# f28002x_cpu_sys_regs register map
Vendor: Texas Instruments
Peripheral module from a debugger description file (folder C2000).
Address unit: 16 bits
Registers are 32-bit, read-write, no defined reset value unless marked. A register's access mark holds for its fields unless they carry their own. Offsets are as the file gives them; lines under a group give offsets from that group; [hi:lo] are bit positions; {n}, {i} and the like mark numbered series; 'fields as' and 'values as' point back to an identical list; <NAME> marks a mode.

## CPU_SYS_REGS — CPU SYS Registers
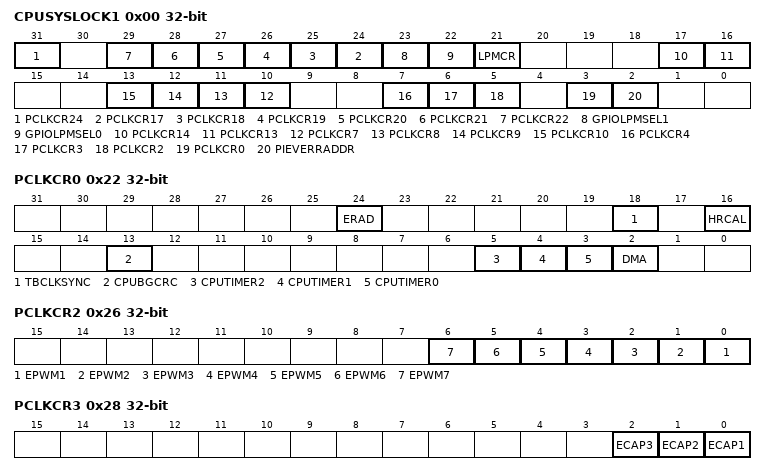
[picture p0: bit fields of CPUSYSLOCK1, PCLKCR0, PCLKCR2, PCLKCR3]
0x00 CPUSYSLOCK1 — Lock bit for CPUSYS registers
  [31] PCLKCR24 — Lock bit for PCLKCR24 Register
  [n+7] PCLKCR{n} (n=17..22) — Lock bit for PCLKCR{n} Register
  [23] GPIOLPMSEL1 — Lock bit for GPIOLPMSEL1 Register
  [22] GPIOLPMSEL0 — Lock bit for GPIOLPMSEL0 Register
  [21] LPMCR — Lock bit for LPMCR Register
  [17] PCLKCR14 — Lock bit for PCLKCR14 Register
  [16] PCLKCR13 — Lock bit for PCLKCR13 Register
  [n+3] PCLKCR{n} (n=7..10) — Lock bit for PCLKCR{n} Register
  [7] PCLKCR4 — Lock bit for PCLKCR4 Register
  [6] PCLKCR3 — Lock bit for PCLKCR3 Register
  [5] PCLKCR2 — Lock bit for PCLKCR2 Register
  [3] PCLKCR0 — Lock bit for PCLKCR0 Register
  [2] PIEVERRADDR — Lock bit for PIEVERRADDR Register
0x02 CPUSYSLOCK2 — Lock bit for CPUSYS registers
  [1] PCLKCR25 — Lock bit for PCLKCR25 Register
0x0A PIEVERRADDR — PIE Vector Fetch Error Address register
  [21:0] ADDR — PIE Vector Fetch Error Handler Routine Address
0x22 PCLKCR0 — Peripheral Clock Gating Registers
  [24] ERAD — ERAD module clock enable
  [18] TBCLKSYNC — EPWM Time Base Clock sync
  [16] HRCAL — HRCAL Clock Enable Bit
  [13] CPUBGCRC — CPUBGCRC Clock Enable Bit
  [5] CPUTIMER2 — CPUTIMER2 Clock Enable bit
  [4] CPUTIMER1 — CPUTIMER1 Clock Enable bit
  [3] CPUTIMER0 — CPUTIMER0 Clock Enable bit
  [2] DMA — DMA Clock Enable bit
0x26 PCLKCR2 — Peripheral Clock Gating Register - ETPWM
  [n-1] EPWM{n} (n=1..7) — EPWM{n} Clock Enable bit
0x28 PCLKCR3 — Peripheral Clock Gating Register - ECAP
  [2] ECAP3 — ECAP3 Clock Enable bit
  [1] ECAP2 — ECAP2 Clock Enable bit
  [0] ECAP1 — ECAP1 Clock Enable bit
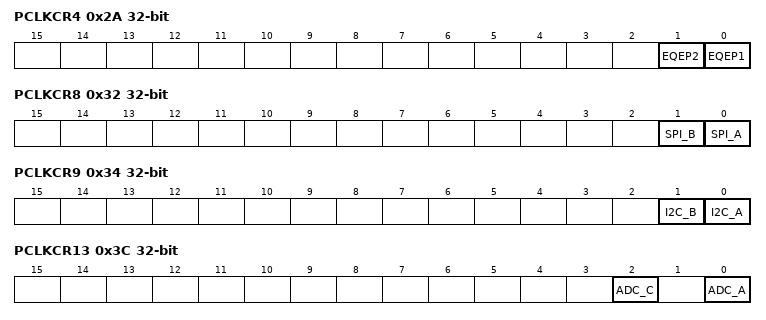
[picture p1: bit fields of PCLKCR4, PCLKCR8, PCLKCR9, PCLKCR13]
0x2A PCLKCR4 — Peripheral Clock Gating Register - EQEP
  [1] EQEP2 — EQEP2 Clock Enable bit
  [0] EQEP1 — EQEP1 Clock Enable bit
0x30 PCLKCR7 — Peripheral Clock Gating Register - SCI
  [0] SCI_A — SCI_A Clock Enable bit
0x32 PCLKCR8 — Peripheral Clock Gating Register - SPI
  [1] SPI_B — SPI_B Clock Enable bit
  [0] SPI_A — SPI_A Clock Enable bit
0x34 PCLKCR9 — Peripheral Clock Gating Register - I2C
  [1] I2C_B — I2C_B Clock Enable bit
  [0] I2C_A — I2C_A Clock Enable bit
0x36 PCLKCR10 — Peripheral Clock Gating Register - CAN
  [0] CAN_A — CAN_A Clock Enable bit
0x3C PCLKCR13 — Peripheral Clock Gating Register - ADC
  [2] ADC_C — ADC_C Clock Enable bit
  [0] ADC_A — ADC_A Clock Enable bit
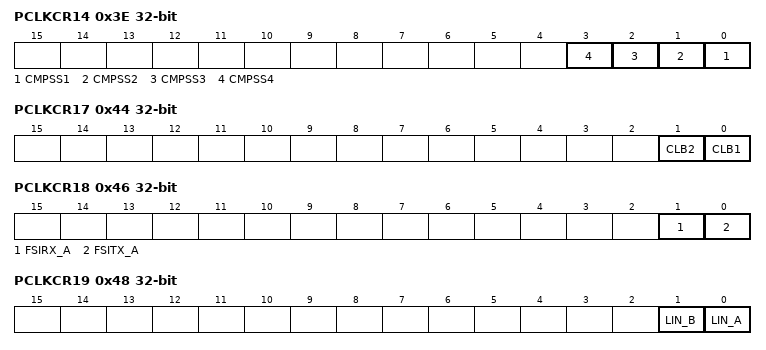
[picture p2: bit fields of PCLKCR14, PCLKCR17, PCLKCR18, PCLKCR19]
0x3E PCLKCR14 — Peripheral Clock Gating Register - CMPSS
  [n-1] CMPSS{n} (n=1..4) — CMPSS{n} Clock Enable bit
0x44 PCLKCR17 — Peripheral Clock Gating Register - CLB
  [1] CLB2 — CLB2 Clock Enable bit
  [0] CLB1 — CLB1 Clock Enable bit
0x46 PCLKCR18 — Peripheral Clock Gating Register - FSI
  [1] FSIRX_A — FSIRX_A Clock Enable bit
  [0] FSITX_A — FSITX_A Clock Enable bit
0x48 PCLKCR19 — Peripheral Clock Gating Register - LIN
  [1] LIN_B — LIN_B Clock Enable bit
  [0] LIN_A — LIN_A Clock Enable bit
0x4A PCLKCR20 — Peripheral Clock Gating Register - PMBUS
  [0] PMBUS_A — PMBUS_A Clock Enable bit
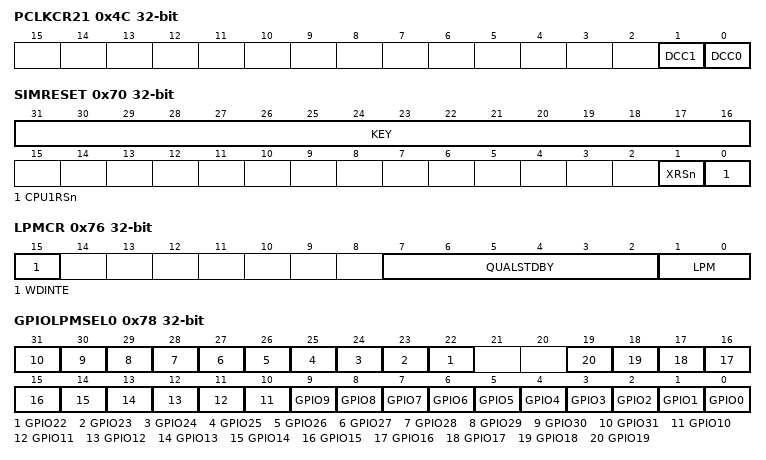
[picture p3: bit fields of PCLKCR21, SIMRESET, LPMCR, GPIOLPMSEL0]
0x4C PCLKCR21 — Peripheral Clock Gating Register - DCC
  [1] DCC1 — DCC1 Clock Enable Bit
  [0] DCC0 — DCC0 Clock Enable Bit
0x4E PCLKCR22 — Peripheral Clock Gating Register - PBIST
  [0] MPOSTCLK_0 — MPOSTCLK_0 Clock Enable Bit
0x52 PCLKCR24 — Peripheral Clock Gating Register - CPUCRC
  [0] CPUCRC — CPUCRC Clock Enable Bit
0x54 PCLKCR25 access not given — Peripheral Clock Gating Register - HIC
0x70 SIMRESET — Simulated Reset Register
  [31:16] KEY — Key value to enable write
  [1] XRSn — Generates a simulated XRSn
  [0] CPU1RSn — Generates a reset to CPU
0x76 LPMCR — LPM Control Register
  [15] WDINTE — Enable for WDINT wakeup from STANDBY
  [7:2] QUALSTDBY — STANDBY Wakeup Pin Qualification Setting
  [1:0] LPM — Low Power Mode setting
0x78 GPIOLPMSEL0 — GPIO LPM Wakeup select registers
  [n] GPIO{n} (n=22..31) — GPIO{n} Enable for LPM Wakeup
  [n] GPIO{n} (n=0..19) — GPIO{n} Enable for LPM Wakeup
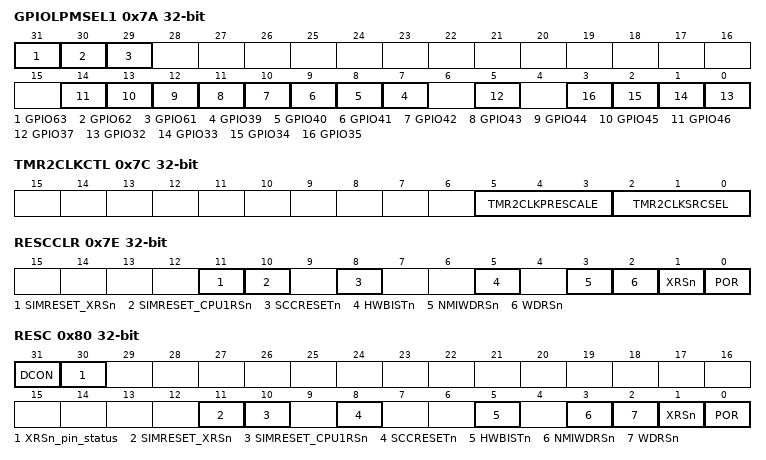
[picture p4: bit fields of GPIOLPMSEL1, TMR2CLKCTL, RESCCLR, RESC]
0x7A GPIOLPMSEL1 — GPIO LPM Wakeup select registers
  [31] GPIO63 — GPIO63 Enable for LPM Wakeup
  [30] GPIO62 — GPIO62 Enable for LPM Wakeup
  [29] GPIO61 — GPIO61 Enable for LPM Wakeup
  [n-32] GPIO{n} (n=39..46) — GPIO{n} Enable for LPM Wakeup
  [5] GPIO37 — GPIO37 Enable for LPM Wakeup
  [n-32] GPIO{n} (n=32..35) — GPIO{n} Enable for LPM Wakeup
0x7C TMR2CLKCTL — Timer2 Clock Measurement functionality control register
  [5:3] TMR2CLKPRESCALE — CPU Timer 2 Clock Pre-Scale Value
  [2:0] TMR2CLKSRCSEL — CPU Timer 2 Clock Source Select Bit
0x7E RESCCLR — Reset Cause Clear Register
  [11] SIMRESET_XRSn — SIMRESET_XRSn Reset Cause Indication Bit
  [10] SIMRESET_CPU1RSn — SIMRESET_CPU1RSn Reset Cause Indication Bit
  [8] SCCRESETn — SCCRESETn Reset Cause Indication Bit
  [5] HWBISTn — HWBISTn Reset Cause Indication Bit
  [3] NMIWDRSn — NMIWDRSn Reset Cause Indication Bit
  [2] WDRSn — WDRSn Reset Cause Indication Bit
  [1] XRSn — XRSn Reset Cause Indication Bit
  [0] POR — POR Reset Cause Indication Bit
0x80 RESC ro — Reset Cause register
  [31] DCON — Debugger conntion status to C28x
  [30] XRSn_pin_status
  [11] SIMRESET_XRSn — SIMRESET_XRSn Reset Cause Indication Bit
  [10] SIMRESET_CPU1RSn — SIMRESET_CPU1RSn Reset Cause Indication Bit
  [8] SCCRESETn — SCCRESETn Reset Cause Indication Bit
  [5] HWBISTn — HWBISTn Reset Cause Indication Bit
  [3] NMIWDRSn — NMIWDRSn Reset Cause Indication Bit
  [2] WDRSn — WDRSn Reset Cause Indication Bit
  [1] XRSn — XRSn Reset Cause Indication Bit
  [0] POR — POR Reset Cause Indication Bit
0x9C CLKSTOPREQ — Peripheral Clock Stop Request Register
  [31:16] KEY — Key for register write
0x9E CLKSTOPACK access not given — Peripheral Clock Stop Ackonwledge Register
